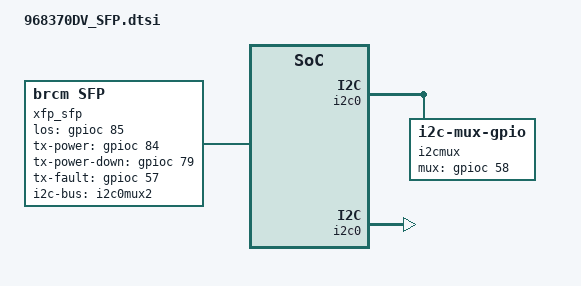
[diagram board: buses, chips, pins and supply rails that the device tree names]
/ {
    xfp_sfp: xfp_sfp {
        pinctrl-names = "default", "tx-sd";
        pinctrl-0 = <&pon_lbe_p_pin_30>;
        pinctrl-1 = <&pon_lbe_p_pin_30 &rogue_onu_in_pin_89>;
        compatible = "brcm,sfp";
        i2c-bus = <&i2c0mux2>;
        los-gpio = <&gpioc 85 GPIO_ACTIVE_HIGH>;
        mod-def0 = <&bca_extintr 56 GPIO_ACTIVE_LOW (BCA_EXTINTR_TYPE_BOTH_EDGE | BCA_EXTINTR_TYPE_SENSE_EDGE)>;
        tx-power-gpio = <&gpioc 84 GPIO_ACTIVE_HIGH>;
        tx-power-down-gpio = <&gpioc 79 GPIO_ACTIVE_HIGH>;
        tx-fault-gpio = <&gpioc 57 GPIO_ACTIVE_HIGH>;
    };

    wan_serdes {
        status = "okay";
        trx = <&xfp_sfp>;
    };

    i2cmux {
        compatible = "i2c-mux-gpio";
        #address-cells = <1>;
        #size-cells = <0>;
        mux-gpios = <&gpioc 58 GPIO_ACTIVE_HIGH>;
        i2c-parent = <&i2c0>;

        i2c0mux1: i2c@1 {
            reg = <0>;
            #address-cells = <1>;
            #size-cells = <0>;
        };

        i2c0mux2: i2c@2 {
            reg = <1>;
            #address-cells = <1>;
            #size-cells = <0>;
        };
    };
};

&i2c0 {
    pinctrl-0 = <&i2c_scl_pin_28 &i2c_sda_pin_29>;
    pinctrl-names = "default";
    status = "okay";
};

&mdio_bus {
    wan_ae {
        trx = <&xfp_sfp>;
        status = "okay";
    };
};
